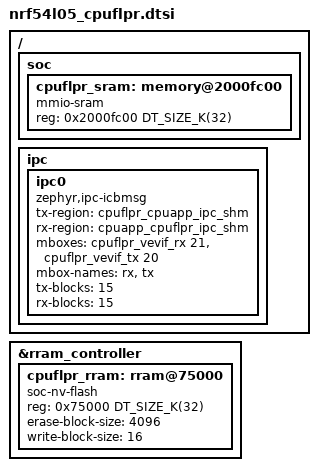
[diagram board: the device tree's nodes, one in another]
/*
 * Copyright (c) 2026 Nordic Semiconductor ASA
 *
 * SPDX-License-Identifier: Apache-2.0
 */

#include <nordic/nrf54l05.dtsi>
#include <riscv/nordic/nrf54l_05_10_15_cpuflpr.dtsi>

/* 59 (APP RAM) + 4 (IPC memory) + 32 (FLPR RAM) + 1 (FLPR hibernation) = 96KB */
/ {
	soc {
		cpuflpr_sram: memory@2000fc00 {
			compatible = "mmio-sram";
			reg = <0x2000fc00 DT_SIZE_K(32)>;
			#address-cells = <1>;
			#size-cells = <1>;
			ranges = <0x0 0x2000fc00 DT_SIZE_K(32)>;
		};
	};

	ipc {
		ipc0: ipc0 {
			compatible = "zephyr,ipc-icbmsg";
			tx-region = <&cpuflpr_cpuapp_ipc_shm>;
			rx-region = <&cpuapp_cpuflpr_ipc_shm>;
			mboxes = <&cpuflpr_vevif_rx 21>, <&cpuflpr_vevif_tx 20>;
			mbox-names = "rx", "tx";
			tx-blocks = <15>;
			rx-blocks = <15>;
			status = "okay";
		};
	};
};

&rram_controller {
	cpuflpr_rram: rram@75000 {
		compatible = "soc-nv-flash";
		reg = <0x75000 DT_SIZE_K(32)>;
		ranges = <0x0 0x75000 DT_SIZE_K(32)>;
		#address-cells = <1>;
		#size-cells = <1>;
		erase-block-size = <4096>;
		write-block-size = <16>;
	};
};
